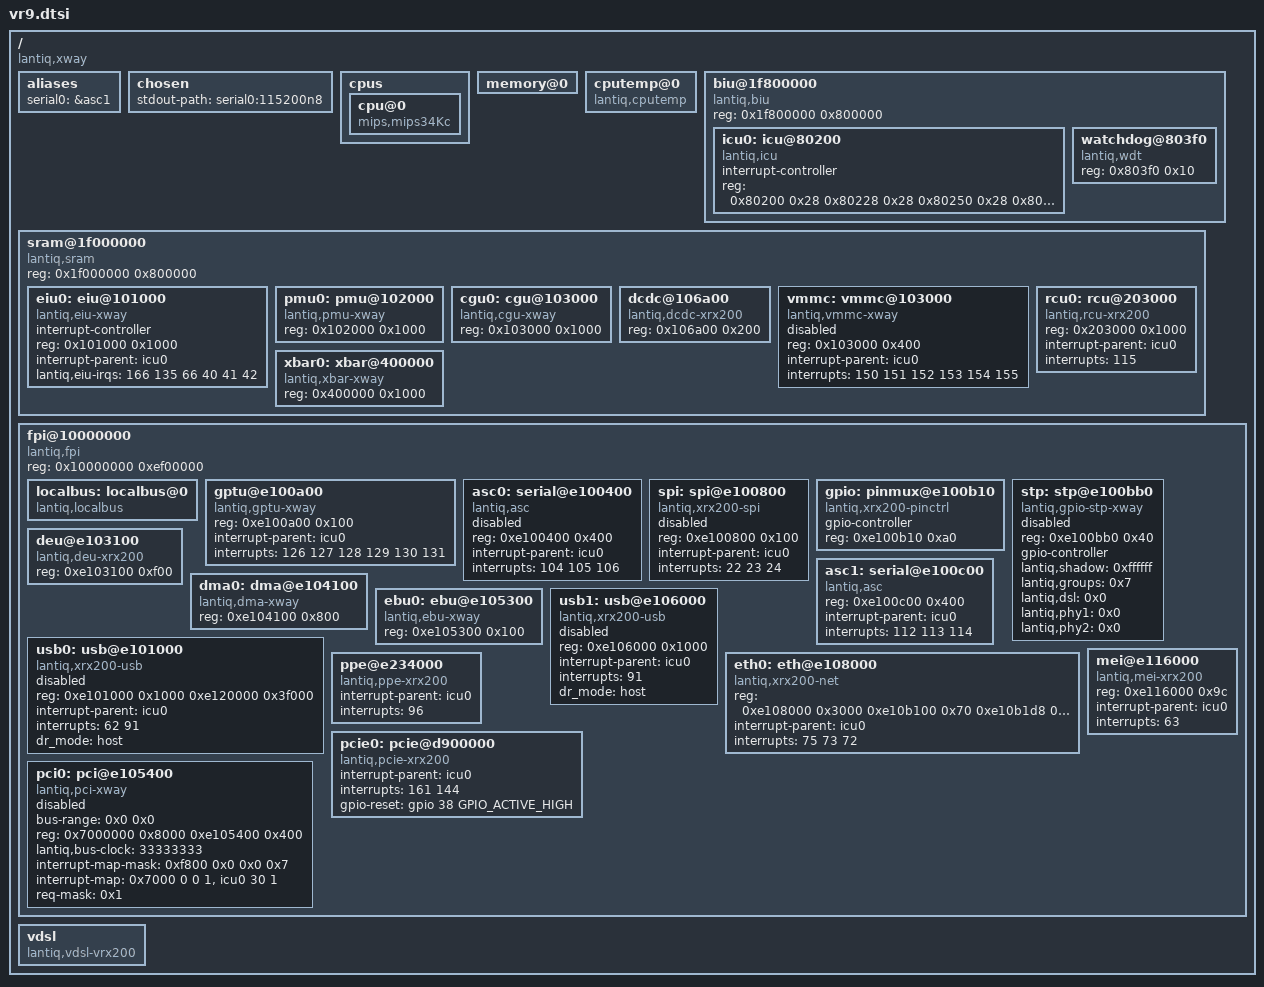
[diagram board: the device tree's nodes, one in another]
#include <dt-bindings/gpio/gpio.h>

/ {
	#address-cells = <1>;
	#size-cells = <1>;
	compatible = "lantiq,xway", "lantiq,vr9";

	aliases {
		serial0 = &asc1;
	};

	chosen {
		stdout-path = "serial0:115200n8";
	};

	cpus {
		cpu@0 {
			compatible = "mips,mips34Kc";
		};
	};

	memory@0 {
		device_type = "memory";
	};

	cputemp@0 {
		compatible = "lantiq,cputemp";
	};

	biu@1f800000 {
		#address-cells = <1>;
		#size-cells = <1>;
		compatible = "lantiq,biu", "simple-bus";
		reg = <0x1f800000 0x800000>;
		ranges = <0x0 0x1f800000 0x7fffff>;

		icu0: icu@80200 {
			#interrupt-cells = <1>;
			interrupt-controller;
			compatible = "lantiq,icu";
			reg = <0x80200 0x28
				0x80228 0x28
				0x80250 0x28
				0x80278 0x28
				0x802a0 0x28>;
		};

		watchdog@803f0 {
			compatible = "lantiq,wdt";
			reg = <0x803f0 0x10>;
		};
	};

	sram@1f000000 {
		#address-cells = <1>;
		#size-cells = <1>;
		compatible = "lantiq,sram", "simple-bus";
		reg = <0x1f000000 0x800000>;
		ranges = <0x0 0x1f000000 0x7fffff>;

		eiu0: eiu@101000 {
			#interrupt-cells = <1>;
			interrupt-controller;
			compatible = "lantiq,eiu-xway";
			reg = <0x101000 0x1000>;
			interrupt-parent = <&icu0>;
			lantiq,eiu-irqs = <166 135 66 40 41 42>;
		};

		pmu0: pmu@102000 {
			compatible = "lantiq,pmu-xway";
			reg = <0x102000 0x1000>;
		};

		cgu0: cgu@103000 {
			compatible = "lantiq,cgu-xway";
			reg = <0x103000 0x1000>;
		};

		dcdc@106a00 {
			compatible = "lantiq,dcdc-xrx200";
			reg = <0x106a00 0x200>;
		};

		vmmc: vmmc@103000 {
			status = "disabled";
			compatible = "lantiq,vmmc-xway";
			reg = <0x103000 0x400>;
			interrupt-parent = <&icu0>;
			interrupts = <150 151 152 153 154 155>;
		};

		rcu0: rcu@203000 {
			compatible = "lantiq,rcu-xrx200";
			reg = <0x203000 0x1000>;
			/* irq for thermal sensor */
			interrupt-parent = <&icu0>;
			interrupts = <115>;
		};

		xbar0: xbar@400000 {
			compatible = "lantiq,xbar-xway";
			reg = <0x400000 0x1000>;
		};
	};

	fpi@10000000 {
		#address-cells = <1>;
		#size-cells = <1>;
		compatible = "lantiq,fpi", "simple-bus";
		ranges = <0x0 0x10000000 0xeefffff>;
		reg = <0x10000000 0xef00000>;

		localbus: localbus@0 {
			#address-cells = <2>;
			#size-cells = <1>;
			ranges = <0 0 0x0 0x3ffffff /* addrsel0 */
				1 0 0x4000000 0x4000010>; /* addsel1 */
			compatible = "lantiq,localbus", "simple-bus";
		};

		gptu@e100a00 {
			compatible = "lantiq,gptu-xway";
			reg = <0xe100a00 0x100>;
			interrupt-parent = <&icu0>;
			interrupts = <126 127 128 129 130 131>;
		};

		asc0: serial@e100400 {
			compatible = "lantiq,asc";
			reg = <0xe100400 0x400>;
			interrupt-parent = <&icu0>;
			interrupts = <104 105 106>;
			status = "disabled";
		};

		spi: spi@e100800 {
			compatible = "lantiq,xrx200-spi", "lantiq,xrx100-spi";
			reg = <0xe100800 0x100>;
			interrupt-parent = <&icu0>;
			interrupts = <22 23 24>;
			interrupt-names = "spi_rx", "spi_tx", "spi_err",
					"spi_frm";
			#address-cells = <1>;
			#size-cells = <1>;
			status = "disabled";
		};

		gpio: pinmux@e100b10 {
			compatible = "lantiq,xrx200-pinctrl";
			#gpio-cells = <2>;
			gpio-controller;
			reg = <0xe100b10 0xa0>;
		};

		stp: stp@e100bb0 {
			status = "disabled";
			compatible = "lantiq,gpio-stp-xway";
			reg = <0xe100bb0 0x40>;
			#gpio-cells = <2>;
			gpio-controller;

			lantiq,shadow = <0xffffff>;
			lantiq,groups = <0x7>;
			lantiq,dsl = <0x0>;
			lantiq,phy1 = <0x0>;
			lantiq,phy2 = <0x0>;
		};

		asc1: serial@e100c00 {
			compatible = "lantiq,asc";
			reg = <0xe100c00 0x400>;
			interrupt-parent = <&icu0>;
			interrupts = <112 113 114>;
		};

		deu@e103100 {
			compatible = "lantiq,deu-xrx200";
			reg = <0xe103100 0xf00>;
		};

		dma0: dma@e104100 {
			compatible = "lantiq,dma-xway";
			reg = <0xe104100 0x800>;
		};

		ebu0: ebu@e105300 {
			compatible = "lantiq,ebu-xway";
			reg = <0xe105300 0x100>;
		};

		usb0: usb@e101000 {
			status = "disabled";
			compatible = "lantiq,xrx200-usb", "lantiq,ifxhcd-xrx200";
			reg = <0xe101000 0x1000
				0xe120000 0x3f000>;
			interrupt-parent = <&icu0>;
			interrupts = <62 91>;
			dr_mode = "host";
		};

		usb1: usb@e106000 {
			status = "disabled";
			compatible = "lantiq,xrx200-usb";
			reg = <0xe106000 0x1000>;
			interrupt-parent = <&icu0>;
			interrupts = <91>;
			dr_mode = "host";
		};

		eth0: eth@e108000 {
			#address-cells = <1>;
			#size-cells = <0>;
			compatible = "lantiq,xrx200-net";
			reg = <	0xe108000 0x3000 /* switch */
				0xe10b100 0x70 /* mdio */
				0xe10b1d8 0x30 /* mii */
				0xe10b308 0x30 /* pmac */
			>;
			interrupt-parent = <&icu0>;
			interrupts = <75 73 72>;
		};

		mei@e116000 {
			compatible = "lantiq,mei-xrx200";
			reg = <0xe116000 0x9c>;
			interrupt-parent = <&icu0>;
			interrupts = <63>;
		};

		ppe@e234000 {
			compatible = "lantiq,ppe-xrx200";
			interrupt-parent = <&icu0>;
			interrupts = <96>;
		};

		pcie0: pcie@d900000 {
			compatible = "lantiq,pcie-xrx200";

			#interrupt-cells = <1>;
			#size-cells = <2>;
			#address-cells = <3>;

			interrupt-parent = <&icu0>;
			interrupts = <161 144>;

			device_type = "pci";

			gpio-reset = <&gpio 38 GPIO_ACTIVE_HIGH>;
		};

		pci0: pci@e105400 {
			status = "disabled";

			#address-cells = <3>;
			#size-cells = <2>;
			#interrupt-cells = <1>;
			compatible = "lantiq,pci-xway";
			bus-range = <0x0 0x0>;
			ranges = <0x2000000 0 0x8000000 0x8000000 0 0x2000000   /* pci memory */
				0x1000000 0 0x00000000 0xae00000 0 0x200000>; /* io space */
			reg = <0x7000000 0x8000         /* config space */
				0xe105400 0x400>;       /* pci bridge */
			lantiq,bus-clock = <33333333>;
			interrupt-map-mask = <0xf800 0x0 0x0 0x7>;
			interrupt-map = <0x7000 0 0 1 &icu0 30 1>; /* slot 14, irq 30 */
			req-mask = <0x1>; /* GNT1 */
		};
	};

	vdsl {
		compatible = "lantiq,vdsl-vrx200";
	};
};
